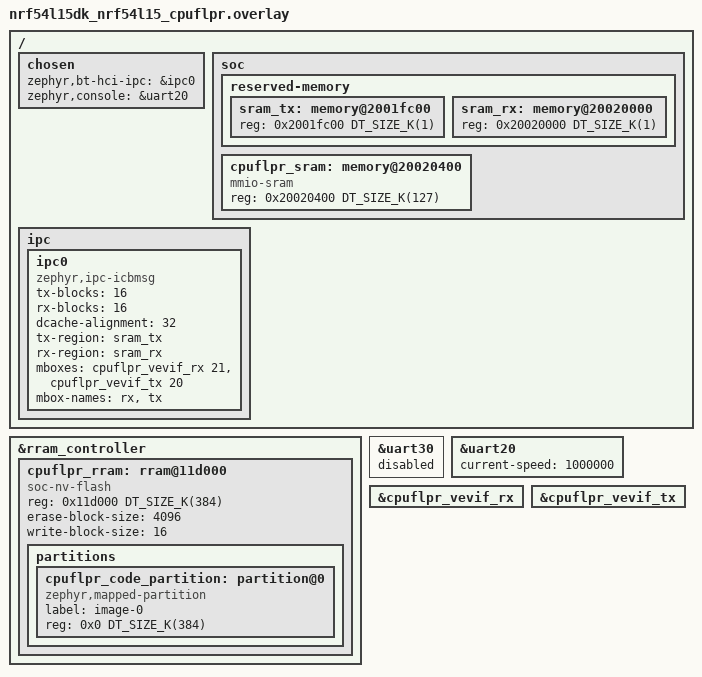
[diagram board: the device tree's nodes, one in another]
/*
 * Copyright (c) 2026 Nordic Semiconductor ASA
 *
 * SPDX-License-Identifier: Apache-2.0
 */

/* SRAM:  127 KB (APP) + 2 KB (IPC) + 127 KB (FLPR) = 256 KB
 * RRAM: 1140 KB (APP) + 384 KB (FLPR) = 1524 KB
 */

/ {
	chosen {
		zephyr,bt-hci-ipc = &ipc0;
		zephyr,console = &uart20;
	};

	soc {
		reserved-memory {
			#address-cells = <1>;
			#size-cells = <1>;

			sram_tx: memory@2001fc00 {
				reg = <0x2001fc00 DT_SIZE_K(1)>;
			};

			sram_rx: memory@20020000 {
				reg = <0x20020000 DT_SIZE_K(1)>;
			};
		};
	};

	ipc {
		ipc0: ipc0 {
			compatible = "zephyr,ipc-icbmsg";
			tx-blocks = <16>;
			rx-blocks = <16>;
			dcache-alignment = <32>;
			tx-region = <&sram_tx>;
			rx-region = <&sram_rx>;
			mboxes = <&cpuflpr_vevif_rx 21>, <&cpuflpr_vevif_tx 20>;
			mbox-names = "rx", "tx";
			status = "okay";
		};
	};
};

/delete-node/ &cpuflpr_sram;
/delete-node/ &cpuflpr_rram;

/ {
	soc {
		cpuflpr_sram: memory@20020400 {
			compatible = "mmio-sram";
			reg = <0x20020400 DT_SIZE_K(127)>;
			#address-cells = <1>;
			#size-cells = <1>;
			ranges = <0x0 0x20020400 DT_SIZE_K(127)>;
		};
	};
};

&rram_controller {
	cpuflpr_rram: rram@11d000 {
		compatible = "soc-nv-flash";
		reg = <0x11d000 DT_SIZE_K(384)>;
		ranges = <0x0 0x11d000 DT_SIZE_K(384)>;
		#address-cells = <1>;
		#size-cells = <1>;
		erase-block-size = <4096>;
		write-block-size = <16>;

		partitions {
			#address-cells = <1>;
			#size-cells = <1>;
			ranges;

			cpuflpr_code_partition: partition@0 {
				label = "image-0";
				compatible = "zephyr,mapped-partition";
				reg = <0x0 DT_SIZE_K(384)>;
			};
		};
	};
};

&uart30 {
	status = "disabled";
};

&uart20 {
	current-speed = <1000000>;
	status = "okay";
};

&cpuflpr_vevif_rx {
	status = "okay";
};

&cpuflpr_vevif_tx {
	status = "okay";
};
